# USB_USB_OCP2SCP_53940000h register map
Vendor: Texas Instruments
Peripheral module from a debugger description file (folder AM261x).
Registers are 32-bit, read-only, reset 0x1 unless marked. A register's access mark holds for its fields unless they carry their own. Offsets are as the file gives them; lines under a group give offsets from that group; [hi:lo] are bit positions; {n}, {i} and the like mark numbered series; 'fields as' and 'values as' point back to an identical list; <NAME> marks a mode.

## USB_OCP2SCP
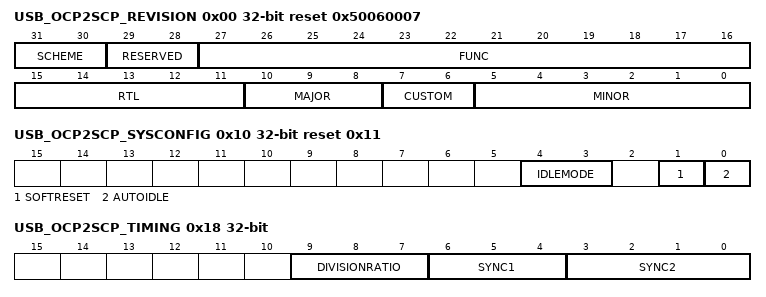
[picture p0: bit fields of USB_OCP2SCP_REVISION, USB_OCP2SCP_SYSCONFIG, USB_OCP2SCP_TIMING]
0x00 USB_OCP2SCP_REVISION reset 0x50060007 — IP Revision Identifier (X.Y.R).
  [31:30] SCHEME — Used to distinguish between old Scheme and current. Spare bit to encode future schemes.
  [29:28] RESERVED — Reads return 0x1
  [27:16] FUNC — Function: Indicates a software compatible module family
  [15:11] RTL — RTL versionThis field changes on bug fix, and resets to
  [10:8] MAJOR — Major RevisionThis field changes when there is a major feature change.This field does not change due to bug fix, or minor feature change.
  [7:6] CUSTOM — Indicates a special version for a particular device. Consequence of use may avoid use of standard Chip Support Library [CSL] / Drivers. 0 if non-custom.
  [5:0] MINOR — Minor RevisionThis field changes when features are scaled up or down.This field does not change due to bug fix, or major feature change.
0x10 USB_OCP2SCP_SYSCONFIG rw reset 0x11 — SYSTEM CONFIGURATION REGISTER.
  [4:3] IDLEMODE — 00 = Force Idle. An idle request is acknowledged unconditionally.01 = No Idle. An idle request is never acknowledged.10 = Smart Idle. The acknowledgement to an idle request is given based on the internal activity [see 4.1.2].11 = Smart Idle Wakeup.
  [1] SOFTRESET — Software Reset. Set this bit to 1 to trigger a module reset. The bit is automatically reset by the hardware. During reads, it always returns 0.0=Normal Mode 1=The module is reset.
  [0] AUTOIDLE — OCP clock gating control.0=Internal Interface OCP clock is free-running 1=Automatic internal OCP clock gating, based on the OCP interface activity
0x14 USB_OCP2SCP_SYSSTATUS — System Status register.
  [0] RESETDONE — 0 = Internal Reset is on-going1 = Reset completed
0x18 USB_OCP2SCP_TIMING rw — Interrupt Status Register (legacy) for first line of interrupt.
  [9:7] DIVISIONRATIO — Division Ration of the SCP clock in relation to OCP input clock.
  [6:4] SYNC1 — Number of SCPclock cycles defining SYNC1
  [3:0] SYNC2 — Number of SCPclock cycles defining SYNC2
